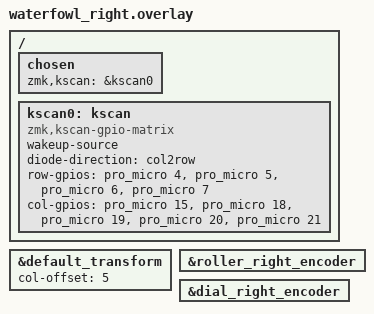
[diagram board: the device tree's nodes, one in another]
/*
 * Copyright (c) 2022 The ZMK Contributors
 *
 * SPDX-License-Identifier: MIT
 */

#include <dt-bindings/zmk/matrix_transform.h>
#include "waterfowl.dtsi"

&default_transform {
    col-offset = <5>;
};

/ {
    chosen {
        zmk,kscan = &kscan0;
    };

    kscan0: kscan {
        compatible = "zmk,kscan-gpio-matrix";
        wakeup-source;

        diode-direction = "col2row";
        row-gpios
            = <&pro_micro 4 (GPIO_ACTIVE_HIGH | GPIO_PULL_DOWN)>
            , <&pro_micro 5 (GPIO_ACTIVE_HIGH | GPIO_PULL_DOWN)>
            , <&pro_micro 6 (GPIO_ACTIVE_HIGH | GPIO_PULL_DOWN)>
            , <&pro_micro 7 (GPIO_ACTIVE_HIGH | GPIO_PULL_DOWN)>
            ;
        col-gpios
            = <&pro_micro 15 GPIO_ACTIVE_HIGH>
            , <&pro_micro 18 GPIO_ACTIVE_HIGH>
            , <&pro_micro 19 GPIO_ACTIVE_HIGH>
            , <&pro_micro 20 GPIO_ACTIVE_HIGH>
            , <&pro_micro 21 GPIO_ACTIVE_HIGH>
            ;
    };

};

&roller_right_encoder {
    status = "okay";
};

&dial_right_encoder {
    status = "okay";
};
